AUTOSAR XML (schema 4.0)
package /Powertrain_Components
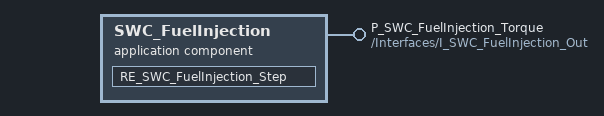
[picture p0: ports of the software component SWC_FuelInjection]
  application sw component type SWC_FuelInjection  # AUTOSAR Application SWC SWC_FuelInjection for Powertrain Control
    provide port P_SWC_FuelInjection_Torque: provided-interface=/Interfaces/I_SWC_FuelInjection_Out
    behavior SWC_FuelInjection_Behavior
      runnable RE_SWC_FuelInjection_Step: symbol=SWC_FuelInjection_Step
  sender receiver interface I_SWC_FuelInjection_Out
    data DE_SWC_FuelInjection_TorqueDemand: type=/AUTOSAR/Platform/uint32
